# Espressif register map
File version: 1.0
CPU: Xtensa LX6 1, little endian, no MPU, FPU, 3 interrupt priority bits
Registers are 32-bit, access not given, reset 0x0 unless marked. A register's access mark holds for its fields unless they carry their own. Offsets are from the block's base; [hi:lo] are bit positions; {n}, {i} and the like mark numbered series.

## SLC
Base 0x3FF58000
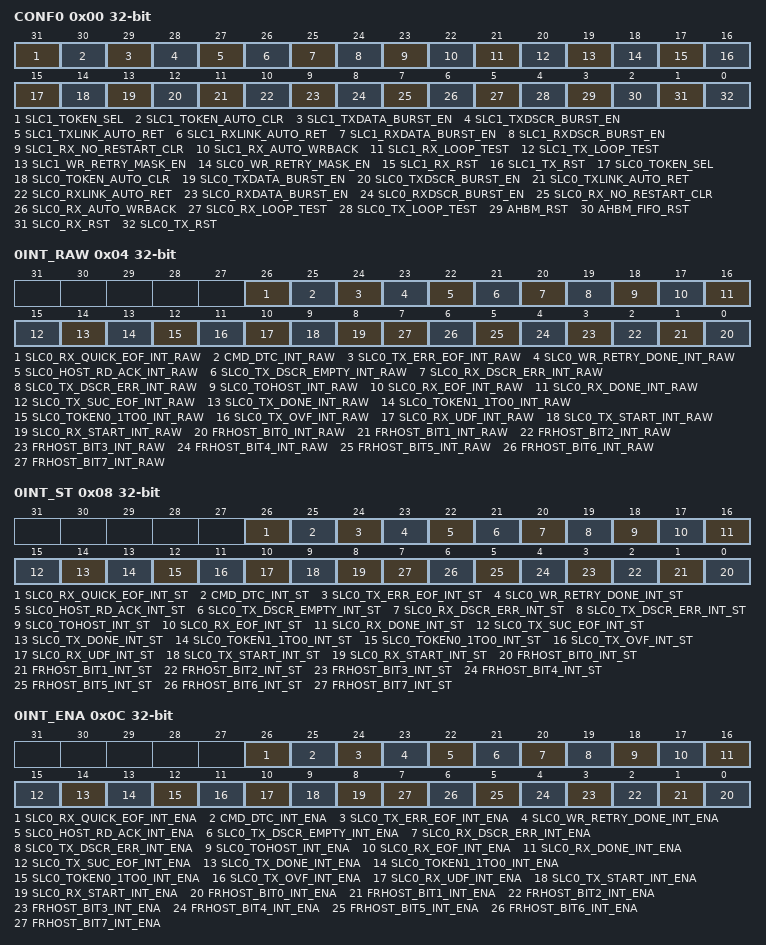
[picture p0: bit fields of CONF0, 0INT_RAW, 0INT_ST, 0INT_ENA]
0x00 CONF0 — SLC_CONF0
  [31] SLC1_TOKEN_SEL, [30] SLC1_TOKEN_AUTO_CLR, [29] SLC1_TXDATA_BURST_EN, [28] SLC1_TXDSCR_BURST_EN, [27] SLC1_TXLINK_AUTO_RET, [26] SLC1_RXLINK_AUTO_RET, [25] SLC1_RXDATA_BURST_EN, [24] SLC1_RXDSCR_BURST_EN, [23] SLC1_RX_NO_RESTART_CLR, [22] SLC1_RX_AUTO_WRBACK, [21] SLC1_RX_LOOP_TEST, [20] SLC1_TX_LOOP_TEST, [19] SLC1_WR_RETRY_MASK_EN, [18] SLC0_WR_RETRY_MASK_EN, [17] SLC1_RX_RST, [16] SLC1_TX_RST, [15] SLC0_TOKEN_SEL, [14] SLC0_TOKEN_AUTO_CLR, [13] SLC0_TXDATA_BURST_EN, [12] SLC0_TXDSCR_BURST_EN, [11] SLC0_TXLINK_AUTO_RET, [10] SLC0_RXLINK_AUTO_RET, [9] SLC0_RXDATA_BURST_EN, [8] SLC0_RXDSCR_BURST_EN, [7] SLC0_RX_NO_RESTART_CLR, [6] SLC0_RX_AUTO_WRBACK, [5] SLC0_RX_LOOP_TEST, [4] SLC0_TX_LOOP_TEST, [3] AHBM_RST, [2] AHBM_FIFO_RST, [1] SLC0_RX_RST, [0] SLC0_TX_RST
0x04 0INT_RAW — SLC_0INT_RAW
  [26] SLC0_RX_QUICK_EOF_INT_RAW, [25] CMD_DTC_INT_RAW, [24] SLC0_TX_ERR_EOF_INT_RAW, [23] SLC0_WR_RETRY_DONE_INT_RAW, [22] SLC0_HOST_RD_ACK_INT_RAW, [21] SLC0_TX_DSCR_EMPTY_INT_RAW, [20] SLC0_RX_DSCR_ERR_INT_RAW, [19] SLC0_TX_DSCR_ERR_INT_RAW, [18] SLC0_TOHOST_INT_RAW, [17] SLC0_RX_EOF_INT_RAW, [16] SLC0_RX_DONE_INT_RAW, [15] SLC0_TX_SUC_EOF_INT_RAW, [14] SLC0_TX_DONE_INT_RAW, [13] SLC0_TOKEN1_1TO0_INT_RAW, [12] SLC0_TOKEN0_1TO0_INT_RAW, [11] SLC0_TX_OVF_INT_RAW, [10] SLC0_RX_UDF_INT_RAW, [9] SLC0_TX_START_INT_RAW, [8] SLC0_RX_START_INT_RAW, [n] FRHOST_BIT{n}_INT_RAW (n=0..7)
0x08 0INT_ST — SLC_0INT_ST
  [26] SLC0_RX_QUICK_EOF_INT_ST, [25] CMD_DTC_INT_ST, [24] SLC0_TX_ERR_EOF_INT_ST, [23] SLC0_WR_RETRY_DONE_INT_ST, [22] SLC0_HOST_RD_ACK_INT_ST, [21] SLC0_TX_DSCR_EMPTY_INT_ST, [20] SLC0_RX_DSCR_ERR_INT_ST, [19] SLC0_TX_DSCR_ERR_INT_ST, [18] SLC0_TOHOST_INT_ST, [17] SLC0_RX_EOF_INT_ST, [16] SLC0_RX_DONE_INT_ST, [15] SLC0_TX_SUC_EOF_INT_ST, [14] SLC0_TX_DONE_INT_ST, [13] SLC0_TOKEN1_1TO0_INT_ST, [12] SLC0_TOKEN0_1TO0_INT_ST, [11] SLC0_TX_OVF_INT_ST, [10] SLC0_RX_UDF_INT_ST, [9] SLC0_TX_START_INT_ST, [8] SLC0_RX_START_INT_ST, [n] FRHOST_BIT{n}_INT_ST (n=0..7)
0x0C 0INT_ENA — SLC_0INT_ENA
  [26] SLC0_RX_QUICK_EOF_INT_ENA, [25] CMD_DTC_INT_ENA, [24] SLC0_TX_ERR_EOF_INT_ENA, [23] SLC0_WR_RETRY_DONE_INT_ENA, [22] SLC0_HOST_RD_ACK_INT_ENA, [21] SLC0_TX_DSCR_EMPTY_INT_ENA, [20] SLC0_RX_DSCR_ERR_INT_ENA, [19] SLC0_TX_DSCR_ERR_INT_ENA, [18] SLC0_TOHOST_INT_ENA, [17] SLC0_RX_EOF_INT_ENA, [16] SLC0_RX_DONE_INT_ENA, [15] SLC0_TX_SUC_EOF_INT_ENA, [14] SLC0_TX_DONE_INT_ENA, [13] SLC0_TOKEN1_1TO0_INT_ENA, [12] SLC0_TOKEN0_1TO0_INT_ENA, [11] SLC0_TX_OVF_INT_ENA, [10] SLC0_RX_UDF_INT_ENA, [9] SLC0_TX_START_INT_ENA, [8] SLC0_RX_START_INT_ENA, [n] FRHOST_BIT{n}_INT_ENA (n=0..7)
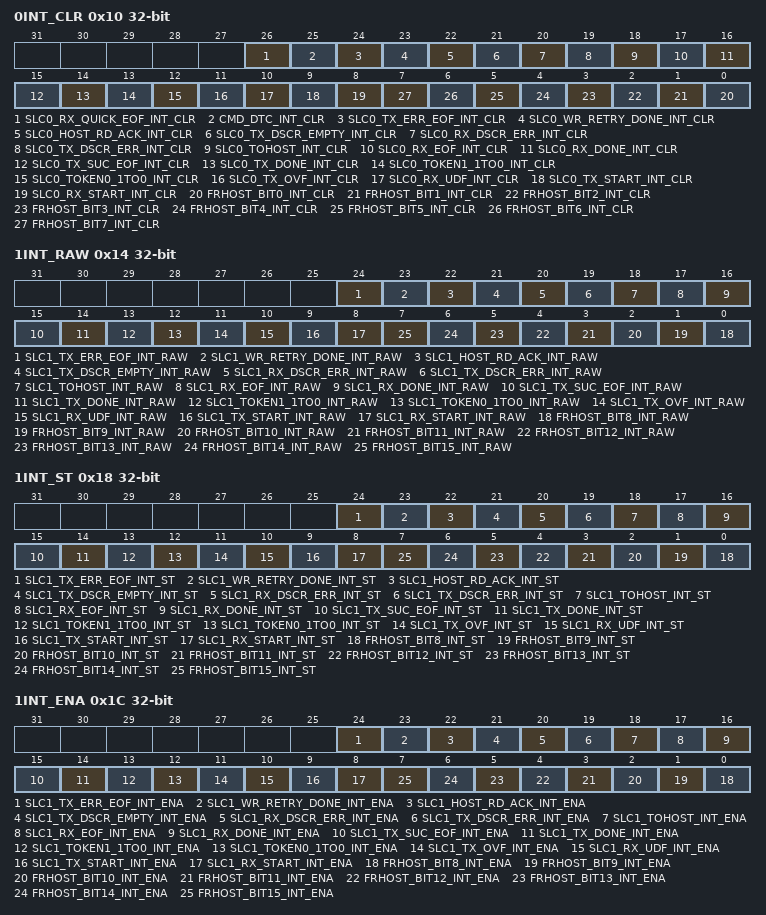
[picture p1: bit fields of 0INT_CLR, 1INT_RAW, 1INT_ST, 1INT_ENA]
0x10 0INT_CLR — SLC_0INT_CLR
  [26] SLC0_RX_QUICK_EOF_INT_CLR, [25] CMD_DTC_INT_CLR, [24] SLC0_TX_ERR_EOF_INT_CLR, [23] SLC0_WR_RETRY_DONE_INT_CLR, [22] SLC0_HOST_RD_ACK_INT_CLR, [21] SLC0_TX_DSCR_EMPTY_INT_CLR, [20] SLC0_RX_DSCR_ERR_INT_CLR, [19] SLC0_TX_DSCR_ERR_INT_CLR, [18] SLC0_TOHOST_INT_CLR, [17] SLC0_RX_EOF_INT_CLR, [16] SLC0_RX_DONE_INT_CLR, [15] SLC0_TX_SUC_EOF_INT_CLR, [14] SLC0_TX_DONE_INT_CLR, [13] SLC0_TOKEN1_1TO0_INT_CLR, [12] SLC0_TOKEN0_1TO0_INT_CLR, [11] SLC0_TX_OVF_INT_CLR, [10] SLC0_RX_UDF_INT_CLR, [9] SLC0_TX_START_INT_CLR, [8] SLC0_RX_START_INT_CLR, [n] FRHOST_BIT{n}_INT_CLR (n=0..7)
0x14 1INT_RAW — SLC_1INT_RAW
  [24] SLC1_TX_ERR_EOF_INT_RAW, [23] SLC1_WR_RETRY_DONE_INT_RAW, [22] SLC1_HOST_RD_ACK_INT_RAW, [21] SLC1_TX_DSCR_EMPTY_INT_RAW, [20] SLC1_RX_DSCR_ERR_INT_RAW, [19] SLC1_TX_DSCR_ERR_INT_RAW, [18] SLC1_TOHOST_INT_RAW, [17] SLC1_RX_EOF_INT_RAW, [16] SLC1_RX_DONE_INT_RAW, [15] SLC1_TX_SUC_EOF_INT_RAW, [14] SLC1_TX_DONE_INT_RAW, [13] SLC1_TOKEN1_1TO0_INT_RAW, [12] SLC1_TOKEN0_1TO0_INT_RAW, [11] SLC1_TX_OVF_INT_RAW, [10] SLC1_RX_UDF_INT_RAW, [9] SLC1_TX_START_INT_RAW, [8] SLC1_RX_START_INT_RAW, [n-8] FRHOST_BIT{n}_INT_RAW (n=8..15)
0x18 1INT_ST — SLC_1INT_ST
  [24] SLC1_TX_ERR_EOF_INT_ST, [23] SLC1_WR_RETRY_DONE_INT_ST, [22] SLC1_HOST_RD_ACK_INT_ST, [21] SLC1_TX_DSCR_EMPTY_INT_ST, [20] SLC1_RX_DSCR_ERR_INT_ST, [19] SLC1_TX_DSCR_ERR_INT_ST, [18] SLC1_TOHOST_INT_ST, [17] SLC1_RX_EOF_INT_ST, [16] SLC1_RX_DONE_INT_ST, [15] SLC1_TX_SUC_EOF_INT_ST, [14] SLC1_TX_DONE_INT_ST, [13] SLC1_TOKEN1_1TO0_INT_ST, [12] SLC1_TOKEN0_1TO0_INT_ST, [11] SLC1_TX_OVF_INT_ST, [10] SLC1_RX_UDF_INT_ST, [9] SLC1_TX_START_INT_ST, [8] SLC1_RX_START_INT_ST, [n-8] FRHOST_BIT{n}_INT_ST (n=8..15)
0x1C 1INT_ENA — SLC_1INT_ENA
  [24] SLC1_TX_ERR_EOF_INT_ENA, [23] SLC1_WR_RETRY_DONE_INT_ENA, [22] SLC1_HOST_RD_ACK_INT_ENA, [21] SLC1_TX_DSCR_EMPTY_INT_ENA, [20] SLC1_RX_DSCR_ERR_INT_ENA, [19] SLC1_TX_DSCR_ERR_INT_ENA, [18] SLC1_TOHOST_INT_ENA, [17] SLC1_RX_EOF_INT_ENA, [16] SLC1_RX_DONE_INT_ENA, [15] SLC1_TX_SUC_EOF_INT_ENA, [14] SLC1_TX_DONE_INT_ENA, [13] SLC1_TOKEN1_1TO0_INT_ENA, [12] SLC1_TOKEN0_1TO0_INT_ENA, [11] SLC1_TX_OVF_INT_ENA, [10] SLC1_RX_UDF_INT_ENA, [9] SLC1_TX_START_INT_ENA, [8] SLC1_RX_START_INT_ENA, [n-8] FRHOST_BIT{n}_INT_ENA (n=8..15)
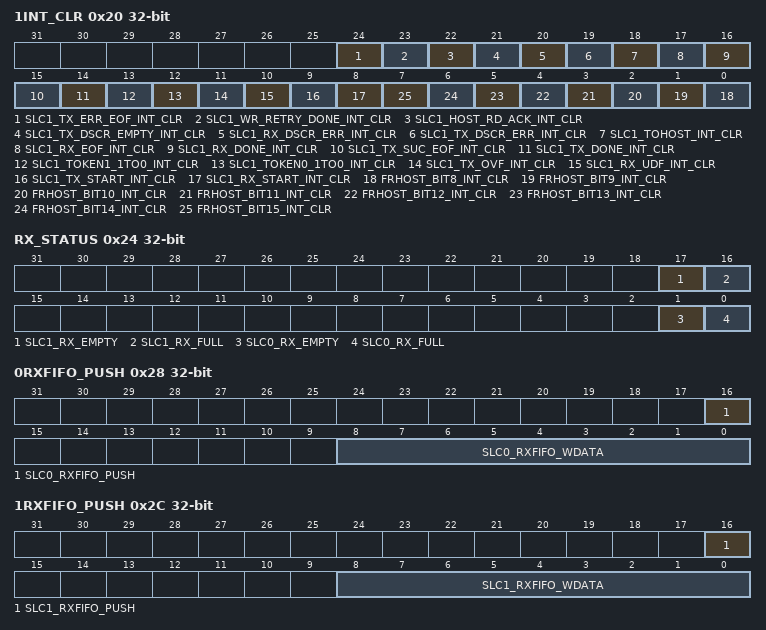
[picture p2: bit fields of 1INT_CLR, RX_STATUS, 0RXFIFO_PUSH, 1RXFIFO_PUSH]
0x20 1INT_CLR — SLC_1INT_CLR
  [24] SLC1_TX_ERR_EOF_INT_CLR, [23] SLC1_WR_RETRY_DONE_INT_CLR, [22] SLC1_HOST_RD_ACK_INT_CLR, [21] SLC1_TX_DSCR_EMPTY_INT_CLR, [20] SLC1_RX_DSCR_ERR_INT_CLR, [19] SLC1_TX_DSCR_ERR_INT_CLR, [18] SLC1_TOHOST_INT_CLR, [17] SLC1_RX_EOF_INT_CLR, [16] SLC1_RX_DONE_INT_CLR, [15] SLC1_TX_SUC_EOF_INT_CLR, [14] SLC1_TX_DONE_INT_CLR, [13] SLC1_TOKEN1_1TO0_INT_CLR, [12] SLC1_TOKEN0_1TO0_INT_CLR, [11] SLC1_TX_OVF_INT_CLR, [10] SLC1_RX_UDF_INT_CLR, [9] SLC1_TX_START_INT_CLR, [8] SLC1_RX_START_INT_CLR, [n-8] FRHOST_BIT{n}_INT_CLR (n=8..15)
0x24 RX_STATUS — SLC_RX_STATUS
  [17] SLC1_RX_EMPTY, [16] SLC1_RX_FULL, [1] SLC0_RX_EMPTY, [0] SLC0_RX_FULL
0x28 0RXFIFO_PUSH — SLC_0RXFIFO_PUSH
  [16] SLC0_RXFIFO_PUSH, [8:0] SLC0_RXFIFO_WDATA
0x2C 1RXFIFO_PUSH — SLC_1RXFIFO_PUSH
  [16] SLC1_RXFIFO_PUSH, [8:0] SLC1_RXFIFO_WDATA
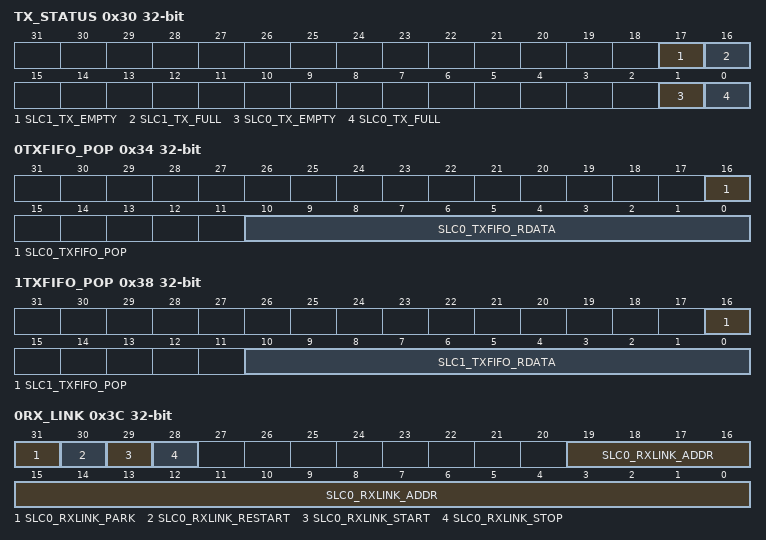
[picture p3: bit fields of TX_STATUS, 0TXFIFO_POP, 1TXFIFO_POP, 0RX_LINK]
0x30 TX_STATUS — SLC_TX_STATUS
  [17] SLC1_TX_EMPTY, [16] SLC1_TX_FULL, [1] SLC0_TX_EMPTY, [0] SLC0_TX_FULL
0x34 0TXFIFO_POP — SLC_0TXFIFO_POP
  [16] SLC0_TXFIFO_POP, [10:0] SLC0_TXFIFO_RDATA
0x38 1TXFIFO_POP — SLC_1TXFIFO_POP
  [16] SLC1_TXFIFO_POP, [10:0] SLC1_TXFIFO_RDATA
0x3C 0RX_LINK — SLC_0RX_LINK
  [31] SLC0_RXLINK_PARK, [30] SLC0_RXLINK_RESTART, [29] SLC0_RXLINK_START, [28] SLC0_RXLINK_STOP, [19:0] SLC0_RXLINK_ADDR
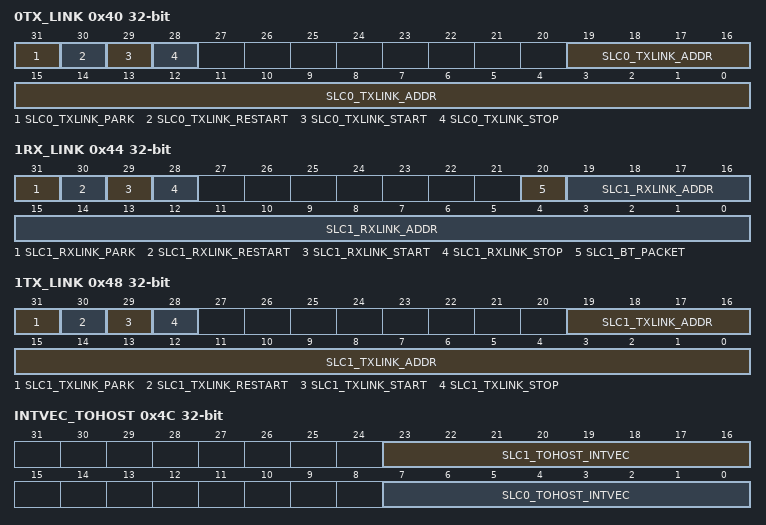
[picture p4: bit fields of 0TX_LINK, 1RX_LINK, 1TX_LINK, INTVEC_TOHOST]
0x40 0TX_LINK — SLC_0TX_LINK
  [31] SLC0_TXLINK_PARK, [30] SLC0_TXLINK_RESTART, [29] SLC0_TXLINK_START, [28] SLC0_TXLINK_STOP, [19:0] SLC0_TXLINK_ADDR
0x44 1RX_LINK — SLC_1RX_LINK
  [31] SLC1_RXLINK_PARK, [30] SLC1_RXLINK_RESTART, [29] SLC1_RXLINK_START, [28] SLC1_RXLINK_STOP, [20] SLC1_BT_PACKET, [19:0] SLC1_RXLINK_ADDR
0x48 1TX_LINK — SLC_1TX_LINK
  [31] SLC1_TXLINK_PARK, [30] SLC1_TXLINK_RESTART, [29] SLC1_TXLINK_START, [28] SLC1_TXLINK_STOP, [19:0] SLC1_TXLINK_ADDR
0x4C INTVEC_TOHOST — SLC_INTVEC_TOHOST
  [23:16] SLC1_TOHOST_INTVEC, [7:0] SLC0_TOHOST_INTVEC
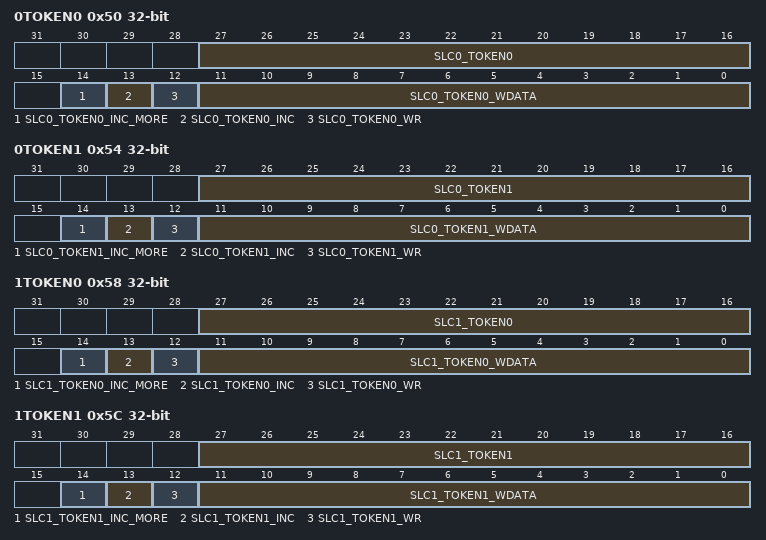
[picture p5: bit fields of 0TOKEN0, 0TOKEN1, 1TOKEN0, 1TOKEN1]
0x50 0TOKEN0 — SLC_0TOKEN0
  [27:16] SLC0_TOKEN0, [14] SLC0_TOKEN0_INC_MORE, [13] SLC0_TOKEN0_INC, [12] SLC0_TOKEN0_WR, [11:0] SLC0_TOKEN0_WDATA
0x54 0TOKEN1 — SLC_0TOKEN1
  [27:16] SLC0_TOKEN1, [14] SLC0_TOKEN1_INC_MORE, [13] SLC0_TOKEN1_INC, [12] SLC0_TOKEN1_WR, [11:0] SLC0_TOKEN1_WDATA
0x58 1TOKEN0 — SLC_1TOKEN0
  [27:16] SLC1_TOKEN0, [14] SLC1_TOKEN0_INC_MORE, [13] SLC1_TOKEN0_INC, [12] SLC1_TOKEN0_WR, [11:0] SLC1_TOKEN0_WDATA
0x5C 1TOKEN1 — SLC_1TOKEN1
  [27:16] SLC1_TOKEN1, [14] SLC1_TOKEN1_INC_MORE, [13] SLC1_TOKEN1_INC, [12] SLC1_TOKEN1_WR, [11:0] SLC1_TOKEN1_WDATA
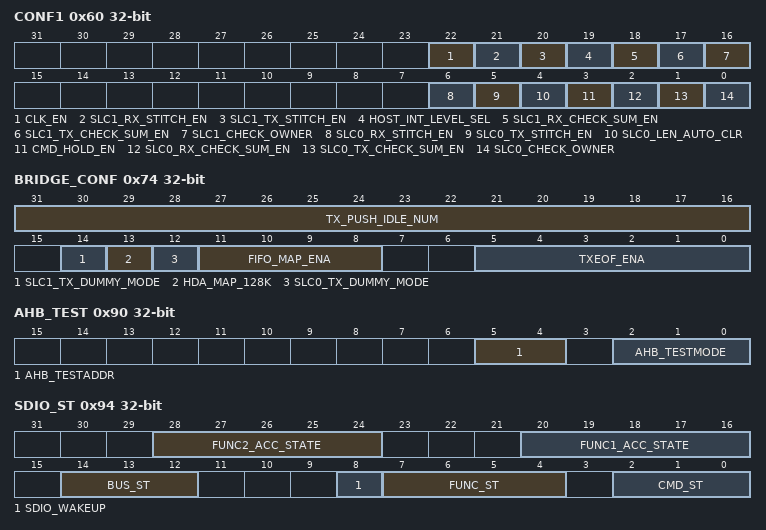
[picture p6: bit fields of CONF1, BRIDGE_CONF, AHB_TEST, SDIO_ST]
0x60 CONF1 — SLC_CONF1
  [22] CLK_EN, [21] SLC1_RX_STITCH_EN, [20] SLC1_TX_STITCH_EN, [19] HOST_INT_LEVEL_SEL, [18] SLC1_RX_CHECK_SUM_EN, [17] SLC1_TX_CHECK_SUM_EN, [16] SLC1_CHECK_OWNER, [6] SLC0_RX_STITCH_EN, [5] SLC0_TX_STITCH_EN, [4] SLC0_LEN_AUTO_CLR, [3] CMD_HOLD_EN, [2] SLC0_RX_CHECK_SUM_EN, [1] SLC0_TX_CHECK_SUM_EN, [0] SLC0_CHECK_OWNER
0x64 0_STATE0 — SLC_0_STATE0
  [31:0] SLC0_STATE0
0x68 0_STATE1 — SLC_0_STATE1
  [31:0] SLC0_STATE1
0x6C 1_STATE0 — SLC_1_STATE0
  [31:0] SLC1_STATE0
0x70 1_STATE1 — SLC_1_STATE1
  [31:0] SLC1_STATE1
0x74 BRIDGE_CONF — SLC_BRIDGE_CONF
  [31:16] TX_PUSH_IDLE_NUM, [14] SLC1_TX_DUMMY_MODE, [13] HDA_MAP_128K, [12] SLC0_TX_DUMMY_MODE, [11:8] FIFO_MAP_ENA, [5:0] TXEOF_ENA
0x78 0_TO_EOF_DES_ADDR — SLC_0_TO_EOF_DES_ADDR
  [31:0] SLC0_TO_EOF_DES_ADDR
0x7C 0_TX_EOF_DES_ADDR — SLC_0_TX_EOF_DES_ADDR
  [31:0] SLC0_TX_SUC_EOF_DES_ADDR
0x80 0_TO_EOF_BFR_DES_ADDR — SLC_0_TO_EOF_BFR_DES_ADDR
  [31:0] SLC0_TO_EOF_BFR_DES_ADDR
0x84 1_TO_EOF_DES_ADDR — SLC_1_TO_EOF_DES_ADDR
  [31:0] SLC1_TO_EOF_DES_ADDR
0x88 1_TX_EOF_DES_ADDR — SLC_1_TX_EOF_DES_ADDR
  [31:0] SLC1_TX_SUC_EOF_DES_ADDR
0x8C 1_TO_EOF_BFR_DES_ADDR — SLC_1_TO_EOF_BFR_DES_ADDR
  [31:0] SLC1_TO_EOF_BFR_DES_ADDR
0x90 AHB_TEST — SLC_AHB_TEST
  [5:4] AHB_TESTADDR, [2:0] AHB_TESTMODE
0x94 SDIO_ST — SLC_SDIO_ST
  [28:24] FUNC2_ACC_STATE, [20:16] FUNC1_ACC_STATE, [14:12] BUS_ST, [8] SDIO_WAKEUP, [7:4] FUNC_ST, [2:0] CMD_ST
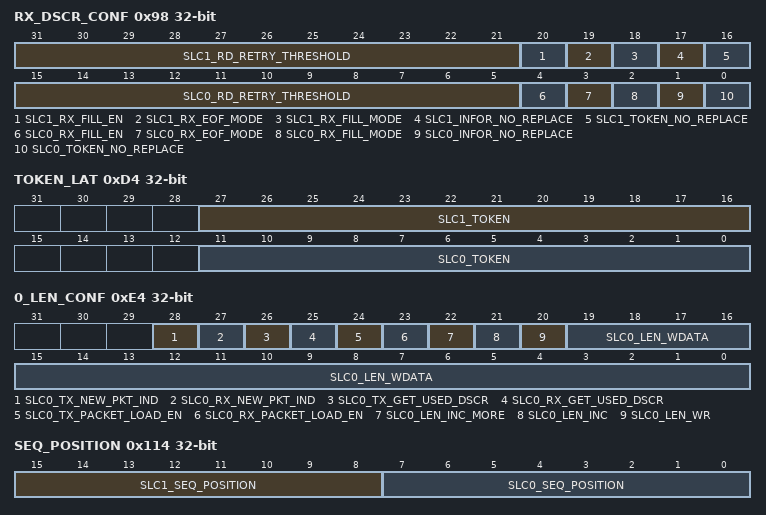
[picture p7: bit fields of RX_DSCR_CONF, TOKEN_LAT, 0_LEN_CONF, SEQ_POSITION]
0x98 RX_DSCR_CONF — SLC_RX_DSCR_CONF
  [31:21] SLC1_RD_RETRY_THRESHOLD, [20] SLC1_RX_FILL_EN, [19] SLC1_RX_EOF_MODE, [18] SLC1_RX_FILL_MODE, [17] SLC1_INFOR_NO_REPLACE, [16] SLC1_TOKEN_NO_REPLACE, [15:5] SLC0_RD_RETRY_THRESHOLD, [4] SLC0_RX_FILL_EN, [3] SLC0_RX_EOF_MODE, [2] SLC0_RX_FILL_MODE, [1] SLC0_INFOR_NO_REPLACE, [0] SLC0_TOKEN_NO_REPLACE
0x9C 0_TXLINK_DSCR — SLC_0_TXLINK_DSCR
  [31:0] SLC0_TXLINK_DSCR
0xA0 0_TXLINK_DSCR_BF0 — SLC_0_TXLINK_DSCR_BF0
  [31:0] SLC0_TXLINK_DSCR_BF0
0xA4 0_TXLINK_DSCR_BF1 — SLC_0_TXLINK_DSCR_BF1
  [31:0] SLC0_TXLINK_DSCR_BF1
0xA8 0_RXLINK_DSCR — SLC_0_RXLINK_DSCR
  [31:0] SLC0_RXLINK_DSCR
0xAC 0_RXLINK_DSCR_BF0 — SLC_0_RXLINK_DSCR_BF0
  [31:0] SLC0_RXLINK_DSCR_BF0
0xB0 0_RXLINK_DSCR_BF1 — SLC_0_RXLINK_DSCR_BF1
  [31:0] SLC0_RXLINK_DSCR_BF1
0xB4 1_TXLINK_DSCR — SLC_1_TXLINK_DSCR
  [31:0] SLC1_TXLINK_DSCR
0xB8 1_TXLINK_DSCR_BF0 — SLC_1_TXLINK_DSCR_BF0
  [31:0] SLC1_TXLINK_DSCR_BF0
0xBC 1_TXLINK_DSCR_BF1 — SLC_1_TXLINK_DSCR_BF1
  [31:0] SLC1_TXLINK_DSCR_BF1
0xC0 1_RXLINK_DSCR — SLC_1_RXLINK_DSCR
  [31:0] SLC1_RXLINK_DSCR
0xC4 1_RXLINK_DSCR_BF0 — SLC_1_RXLINK_DSCR_BF0
  [31:0] SLC1_RXLINK_DSCR_BF0
0xC8 1_RXLINK_DSCR_BF1 — SLC_1_RXLINK_DSCR_BF1
  [31:0] SLC1_RXLINK_DSCR_BF1
0xCC 0_TX_ERREOF_DES_ADDR — SLC_0_TX_ERREOF_DES_ADDR
  [31:0] SLC0_TX_ERR_EOF_DES_ADDR
0xD0 1_TX_ERREOF_DES_ADDR — SLC_1_TX_ERREOF_DES_ADDR
  [31:0] SLC1_TX_ERR_EOF_DES_ADDR
0xD4 TOKEN_LAT — SLC_TOKEN_LAT
  [27:16] SLC1_TOKEN, [11:0] SLC0_TOKEN
0xD8 TX_DSCR_CONF — SLC_TX_DSCR_CONF
  [10:0] WR_RETRY_THRESHOLD
0xDC CMD_INFOR0 — SLC_CMD_INFOR0
  [31:0] CMD_CONTENT0
0xE0 CMD_INFOR1 — SLC_CMD_INFOR1
  [31:0] CMD_CONTENT1
0xE4 0_LEN_CONF — SLC_0_LEN_CONF
  [28] SLC0_TX_NEW_PKT_IND, [27] SLC0_RX_NEW_PKT_IND, [26] SLC0_TX_GET_USED_DSCR, [25] SLC0_RX_GET_USED_DSCR, [24] SLC0_TX_PACKET_LOAD_EN, [23] SLC0_RX_PACKET_LOAD_EN, [22] SLC0_LEN_INC_MORE, [21] SLC0_LEN_INC, [20] SLC0_LEN_WR, [19:0] SLC0_LEN_WDATA
0xE8 0_LENGTH — SLC_0_LENGTH
  [19:0] SLC0_LEN
0xEC 0_TXPKT_H_DSCR — SLC_0_TXPKT_H_DSCR
  [31:0] SLC0_TX_PKT_H_DSCR_ADDR
0xF0 0_TXPKT_E_DSCR — SLC_0_TXPKT_E_DSCR
  [31:0] SLC0_TX_PKT_E_DSCR_ADDR
0xF4 0_RXPKT_H_DSCR — SLC_0_RXPKT_H_DSCR
  [31:0] SLC0_RX_PKT_H_DSCR_ADDR
0xF8 0_RXPKT_E_DSCR — SLC_0_RXPKT_E_DSCR
  [31:0] SLC0_RX_PKT_E_DSCR_ADDR
0xFC 0_TXPKTU_H_DSCR — SLC_0_TXPKTU_H_DSCR
  [31:0] SLC0_TX_PKT_START_DSCR_ADDR
0x100 0_TXPKTU_E_DSCR — SLC_0_TXPKTU_E_DSCR
  [31:0] SLC0_TX_PKT_END_DSCR_ADDR
0x104 0_RXPKTU_H_DSCR — SLC_0_RXPKTU_H_DSCR
  [31:0] SLC0_RX_PKT_START_DSCR_ADDR
0x108 0_RXPKTU_E_DSCR — SLC_0_RXPKTU_E_DSCR
  [31:0] SLC0_RX_PKT_END_DSCR_ADDR
0x114 SEQ_POSITION — SLC_SEQ_POSITION
  [15:8] SLC1_SEQ_POSITION, [7:0] SLC0_SEQ_POSITION
0x118 0_DSCR_REC_CONF — SLC_0_DSCR_REC_CONF
  [9:0] SLC0_RX_DSCR_REC_LIM
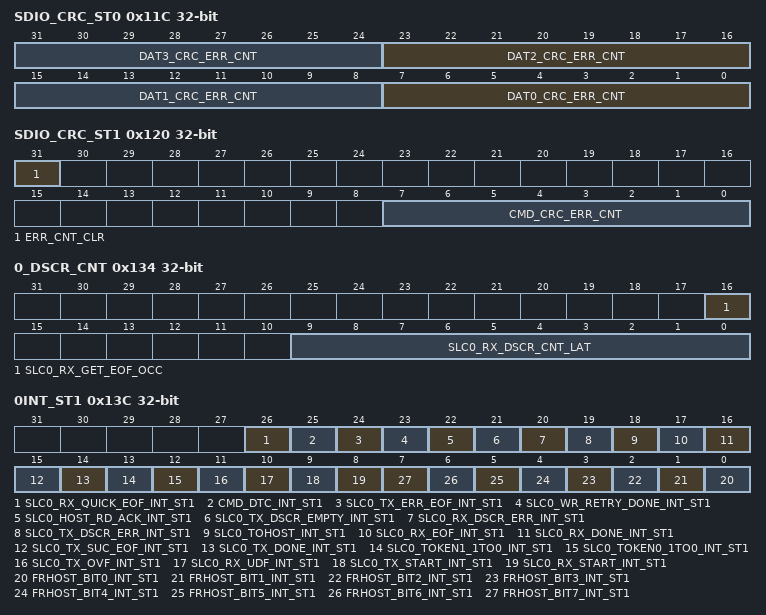
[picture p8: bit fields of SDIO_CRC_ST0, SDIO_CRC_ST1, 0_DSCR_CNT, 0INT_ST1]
0x11C SDIO_CRC_ST0 — SLC_SDIO_CRC_ST0
  [8n+7:8n] DAT{n}_CRC_ERR_CNT (n=0..3)
0x120 SDIO_CRC_ST1 — SLC_SDIO_CRC_ST1
  [31] ERR_CNT_CLR, [7:0] CMD_CRC_ERR_CNT
0x124 0_EOF_START_DES — SLC_0_EOF_START_DES
  [31:0] SLC0_EOF_START_DES_ADDR
0x128 0_PUSH_DSCR_ADDR — SLC_0_PUSH_DSCR_ADDR
  [31:0] SLC0_RX_PUSH_DSCR_ADDR
0x12C 0_DONE_DSCR_ADDR — SLC_0_DONE_DSCR_ADDR
  [31:0] SLC0_RX_DONE_DSCR_ADDR
0x130 0_SUB_START_DES — SLC_0_SUB_START_DES
  [31:0] SLC0_SUB_PAC_START_DSCR_ADDR
0x134 0_DSCR_CNT — SLC_0_DSCR_CNT
  [16] SLC0_RX_GET_EOF_OCC, [9:0] SLC0_RX_DSCR_CNT_LAT
0x138 0_LEN_LIM_CONF — SLC_0_LEN_LIM_CONF
  [19:0] SLC0_LEN_LIM
0x13C 0INT_ST1 — SLC_0INT_ST1
  [26] SLC0_RX_QUICK_EOF_INT_ST1, [25] CMD_DTC_INT_ST1, [24] SLC0_TX_ERR_EOF_INT_ST1, [23] SLC0_WR_RETRY_DONE_INT_ST1, [22] SLC0_HOST_RD_ACK_INT_ST1, [21] SLC0_TX_DSCR_EMPTY_INT_ST1, [20] SLC0_RX_DSCR_ERR_INT_ST1, [19] SLC0_TX_DSCR_ERR_INT_ST1, [18] SLC0_TOHOST_INT_ST1, [17] SLC0_RX_EOF_INT_ST1, [16] SLC0_RX_DONE_INT_ST1, [15] SLC0_TX_SUC_EOF_INT_ST1, [14] SLC0_TX_DONE_INT_ST1, [13] SLC0_TOKEN1_1TO0_INT_ST1, [12] SLC0_TOKEN0_1TO0_INT_ST1, [11] SLC0_TX_OVF_INT_ST1, [10] SLC0_RX_UDF_INT_ST1, [9] SLC0_TX_START_INT_ST1, [8] SLC0_RX_START_INT_ST1, [n] FRHOST_BIT{n}_INT_ST1 (n=0..7)
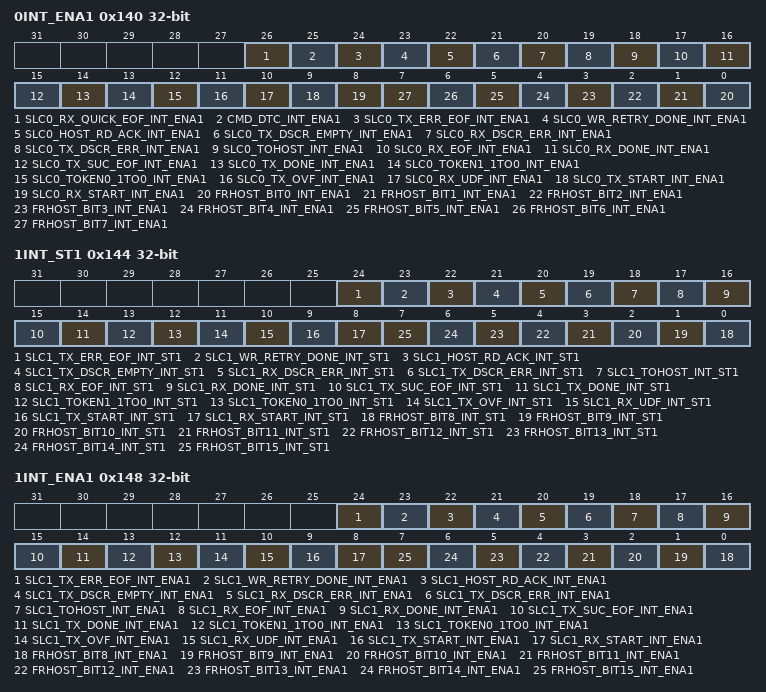
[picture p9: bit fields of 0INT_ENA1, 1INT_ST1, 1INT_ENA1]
0x140 0INT_ENA1 — SLC_0INT_ENA1
  [26] SLC0_RX_QUICK_EOF_INT_ENA1, [25] CMD_DTC_INT_ENA1, [24] SLC0_TX_ERR_EOF_INT_ENA1, [23] SLC0_WR_RETRY_DONE_INT_ENA1, [22] SLC0_HOST_RD_ACK_INT_ENA1, [21] SLC0_TX_DSCR_EMPTY_INT_ENA1, [20] SLC0_RX_DSCR_ERR_INT_ENA1, [19] SLC0_TX_DSCR_ERR_INT_ENA1, [18] SLC0_TOHOST_INT_ENA1, [17] SLC0_RX_EOF_INT_ENA1, [16] SLC0_RX_DONE_INT_ENA1, [15] SLC0_TX_SUC_EOF_INT_ENA1, [14] SLC0_TX_DONE_INT_ENA1, [13] SLC0_TOKEN1_1TO0_INT_ENA1, [12] SLC0_TOKEN0_1TO0_INT_ENA1, [11] SLC0_TX_OVF_INT_ENA1, [10] SLC0_RX_UDF_INT_ENA1, [9] SLC0_TX_START_INT_ENA1, [8] SLC0_RX_START_INT_ENA1, [n] FRHOST_BIT{n}_INT_ENA1 (n=0..7)
0x144 1INT_ST1 — SLC_1INT_ST1
  [24] SLC1_TX_ERR_EOF_INT_ST1, [23] SLC1_WR_RETRY_DONE_INT_ST1, [22] SLC1_HOST_RD_ACK_INT_ST1, [21] SLC1_TX_DSCR_EMPTY_INT_ST1, [20] SLC1_RX_DSCR_ERR_INT_ST1, [19] SLC1_TX_DSCR_ERR_INT_ST1, [18] SLC1_TOHOST_INT_ST1, [17] SLC1_RX_EOF_INT_ST1, [16] SLC1_RX_DONE_INT_ST1, [15] SLC1_TX_SUC_EOF_INT_ST1, [14] SLC1_TX_DONE_INT_ST1, [13] SLC1_TOKEN1_1TO0_INT_ST1, [12] SLC1_TOKEN0_1TO0_INT_ST1, [11] SLC1_TX_OVF_INT_ST1, [10] SLC1_RX_UDF_INT_ST1, [9] SLC1_TX_START_INT_ST1, [8] SLC1_RX_START_INT_ST1, [n-8] FRHOST_BIT{n}_INT_ST1 (n=8..15)
0x148 1INT_ENA1 — SLC_1INT_ENA1
  [24] SLC1_TX_ERR_EOF_INT_ENA1, [23] SLC1_WR_RETRY_DONE_INT_ENA1, [22] SLC1_HOST_RD_ACK_INT_ENA1, [21] SLC1_TX_DSCR_EMPTY_INT_ENA1, [20] SLC1_RX_DSCR_ERR_INT_ENA1, [19] SLC1_TX_DSCR_ERR_INT_ENA1, [18] SLC1_TOHOST_INT_ENA1, [17] SLC1_RX_EOF_INT_ENA1, [16] SLC1_RX_DONE_INT_ENA1, [15] SLC1_TX_SUC_EOF_INT_ENA1, [14] SLC1_TX_DONE_INT_ENA1, [13] SLC1_TOKEN1_1TO0_INT_ENA1, [12] SLC1_TOKEN0_1TO0_INT_ENA1, [11] SLC1_TX_OVF_INT_ENA1, [10] SLC1_RX_UDF_INT_ENA1, [9] SLC1_TX_START_INT_ENA1, [8] SLC1_RX_START_INT_ENA1, [n-8] FRHOST_BIT{n}_INT_ENA1 (n=8..15)
0x1F8 DATE — SLC_DATE
0x1FC ID — SLC_ID
